VERSION ""

NS_ :

BS_:
BU_: roboRio
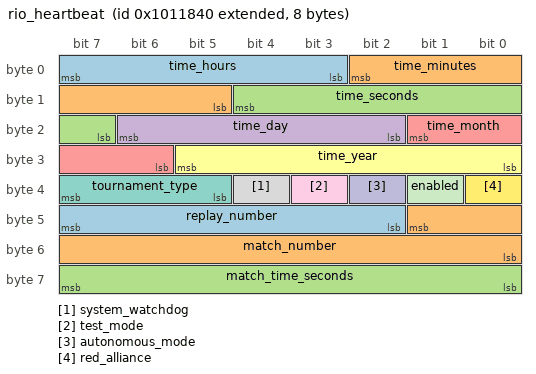
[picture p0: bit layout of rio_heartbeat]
BO_ 2164332608 rio_heartbeat: 8 roboRio
  SG_ time_hours : 7|5@0+ (1,0) [0|23] "" Vector__XXX
  SG_ time_minutes : 2|6@0+ (1,0) [0|59] "" Vector__XXX
  SG_ time_seconds : 12|6@0+ (1,0) [0|59] "" Vector__XXX
  SG_ time_day : 22|5@0+ (1,0) [1|31] "" Vector__XXX
  SG_ time_month : 17|4@0+ (1,0) [0|11] "" Vector__XXX
  SG_ time_year : 29|6@0+ (1,0) [0|63] "" Vector__XXX
  SG_ tournament_type : 39|3@0+ (1,0) [0|3] "" Vector__XXX
  SG_ system_watchdog : 36|1@0+ (1,0) [0|1] "" Vector__XXX
  SG_ test_mode : 35|1@0+ (1,0) [0|1] "" Vector__XXX
  SG_ autonomous_mode : 34|1@0+ (1,0) [0|1] "" Vector__XXX
  SG_ enabled : 33|1@0+ (1,0) [0|1] "" Vector__XXX
  SG_ red_alliance : 32|1@0+ (1,0) [0|1] "" Vector__XXX
  SG_ replay_number : 47|6@0+ (1,0) [0|63] "" Vector__XXX
  SG_ match_number : 41|10@0+ (1,0) [0|1023] "" Vector__XXX
  SG_ match_time_seconds : 63|8@0+ (1,0) [0|255] "" Vector__XXX
